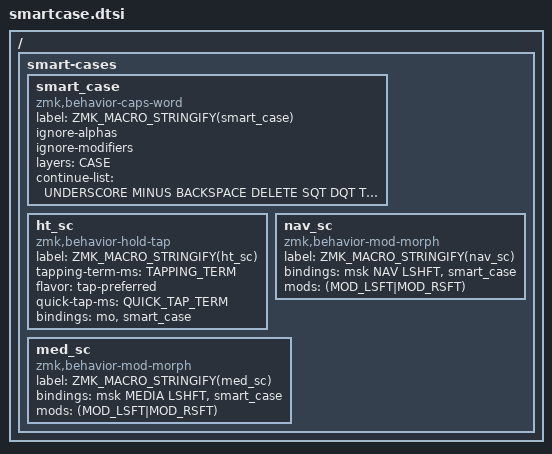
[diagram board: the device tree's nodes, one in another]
/*
*
* Copyright (c) 2022 Rafael Romão
* SPDX-License-Identifier: MIT
*
*/

/ {
    smart-cases {
        smart_case: smart_case {
            compatible = "zmk,behavior-caps-word";
            label = ZMK_MACRO_STRINGIFY(smart_case);
            ignore-alphas;
            ignore-modifiers;
			#binding-cells = <0>;  
            layers = <CASE>;
            continue-list = <UNDERSCORE MINUS BACKSPACE DELETE SQT DQT TILDE CARET GRAVE>;
        };

        ht_sc: ht_sc {
            compatible = "zmk,behavior-hold-tap";
            label = ZMK_MACRO_STRINGIFY(ht_sc);
            #binding-cells = <2>;
            tapping-term-ms = <TAPPING_TERM>;
            flavor = "tap-preferred";
            quick-tap-ms = <QUICK_TAP_TERM>;
            bindings = <&mo>, <&smart_case>;
        };

        nav_sc: nav_sc {
            compatible = "zmk,behavior-mod-morph";
            label = ZMK_MACRO_STRINGIFY(nav_sc);
            #binding-cells = <0>;
            bindings = <&msk NAV LSHFT>, <&smart_case>;
            mods = <(MOD_LSFT|MOD_RSFT)>;
        };

        med_sc: med_sc {
            compatible = "zmk,behavior-mod-morph";
            label = ZMK_MACRO_STRINGIFY(med_sc);
            #binding-cells = <0>;
            bindings = <&msk MEDIA LSHFT>, <&smart_case>;
            mods = <(MOD_LSFT|MOD_RSFT)>;
        };
    };
};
